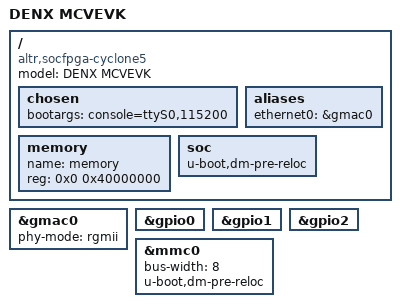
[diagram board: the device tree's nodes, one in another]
/*
 * Copyright (C) 2015 Marek Vasut <marex@denx.de>
 *
 * SPDX-License-Identifier:	GPL-2.0+
 */

#include "socfpga_cyclone5.dtsi"

/ {
	model = "DENX MCVEVK";
	compatible = "altr,socfpga-cyclone5", "altr,socfpga";

	chosen {
		bootargs = "console=ttyS0,115200";
	};

	aliases {
		ethernet0 = &gmac0;
	};

	memory {
		name = "memory";
		device_type = "memory";
		reg = <0x0 0x40000000>; /* 1GB */
	};

	soc {
		u-boot,dm-pre-reloc;
	};
};

&gmac0 {
	status = "okay";
	phy-mode = "rgmii";
};

&gpio0 {
	status = "okay";
};

&gpio1 {
	status = "okay";
};

&gpio2 {
	status = "okay";
};

&mmc0 {
	status = "okay";
	bus-width = <8>;
	u-boot,dm-pre-reloc;
};
